AUTOSAR XML (schema 00051)
package /ComponentTypes
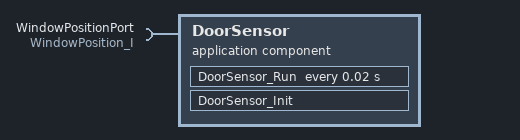
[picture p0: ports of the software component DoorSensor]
  application sw component type DoorSensor
    require port WindowPositionPort: nonqueued-receiver-com-spec{data-element=WindowPosition, init-value=constant-reference=WindowPosition_IV}, required-interface=WindowPosition_I
    behavior DoorSensor_InternalBehavior
      init event IT_DoorSensor_Init: start-on-event=DoorSensor_Init
      timing event TMT_DoorSensor_Run: start-on-event=DoorSensor_Run, period=0.02
      runnable DoorSensor_Init
      runnable DoorSensor_Run
        data-receive-point-by-arguments:
          access REC_WindowPositionPort_WindowPosition: accessed-variable=WindowPositionPort.WindowPosition
  swc implementation DoorSensor_Implementation: behavior=DoorSensor_InternalBehavior
